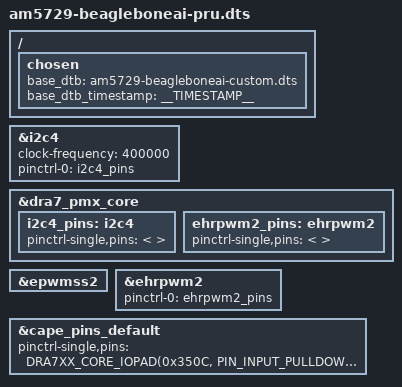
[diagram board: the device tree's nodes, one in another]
#include "am5729-beagleboneai.dts"  
// make it easy to determine which dtb you're currently running on  
// (via /proc/device-tree/chosen/)  
/ {  
 chosen {  
  base_dtb = "am5729-beagleboneai-custom.dts";  
  base_dtb_timestamp = __TIMESTAMP__;  
 };  
};  
// eventually these should be available in a header  
#define P9_14  (0x3400 + 4 * 107)  
#define P9_16  (0x3400 + 4 * 108)  
#define P9_19a (0x3400 + 4 * 16)  
#define P9_19b (0x3400 + 4 * 95)  
#define P9_20a (0x3400 + 4 * 17)  
#define P9_20b (0x3400 + 4 * 94)  
// enable i2c-3 on P9.19 (scl) + P9.20 (sda)  
&i2c4 {  
 status = "okay";  
 clock-frequency = <400000>;  
 pinctrl-names = "default";  
 pinctrl-0 = <&i2c4_pins>;  
};  
&dra7_pmx_core {  
 i2c4_pins: i2c4 {  
  pinctrl-single,pins = <  
   /* DRA7XX_CORE_IOPAD( P9_19a, PIN_INPUT_PULLUP | MUX_MODE7  )  // scl   */
   /* DRA7XX_CORE_IOPAD( P9_19b, PIN_INPUT_PULLUP | MUX_MODE14 )  // (shared pin)   */
   /* DRA7XX_CORE_IOPAD( P9_20a, PIN_INPUT_PULLUP | MUX_MODE7  )  // sda   */
   /* DRA7XX_CORE_IOPAD( P9_20b, PIN_INPUT_PULLUP | MUX_MODE14 )  // (shared pin)   */
  >;  
 };  
};  
// enable pwm-2 on P9.14 (out-A) + P9.16 (out-B)  
&epwmss2 {  
 status = "okay";  
};  
&ehrpwm2 {  
 status = "okay";  
 pinctrl-names = "default";  
 pinctrl-0 = <&ehrpwm2_pins>;  
};  
&dra7_pmx_core {  
 ehrpwm2_pins: ehrpwm2 {  
  pinctrl-single,pins = <  
 //  DRA7XX_CORE_IOPAD( P9_14, PIN_OUTPUT_PULLDOWN | MUX_MODE13 )  // out A  
 //  DRA7XX_CORE_IOPAD( P9_16, PIN_OUTPUT_PULLDOWN | MUX_MODE13 )  // out B  
  >;  
 };  
};  
  
// Here's the obnoxious part: since u-boot doesn't have same pin defaults yet, all pins not  
// explicitly setup above should be overridden here.  This will eventually no longer be needed.  
&cape_pins_default {  
 pinctrl-single,pins = <  
DRA7XX_CORE_IOPAD(0x350C, PIN_INPUT_PULLDOWN | MUX_MODE13) // P8.12(pr1_pru0_gpo3)
DRA7XX_CORE_IOPAD(0x3510, PIN_INPUT_PULLDOWN | MUX_MODE13) // P8.11(pr1_pru0_gpo4)
DRA7XX_CORE_IOPAD(0x3514, PIN_INPUT_PULLDOWN | MUX_MODE13) // P9.15(pr1_pru0_gpo5)
DRA7XX_CORE_IOPAD(0x3544, PIN_INPUT_PULLDOWN | MUX_MODE13) // P9.26(pr1_pru0_gpo17)
DRA7XX_CORE_IOPAD(0x3578, PIN_INPUT_PULLDOWN | MUX_MODE13) // P9.20(pr1_pru1_gpo1)
DRA7XX_CORE_IOPAD(0x357C, PIN_INPUT_PULLDOWN | MUX_MODE13) // P9.19(pr1_pru1_gpo2)
DRA7XX_CORE_IOPAD(0x3580, PIN_INPUT_PULLDOWN | MUX_MODE13) // P9.41(pr1_pru1_gpo3)
DRA7XX_CORE_IOPAD(0x3588, PIN_INPUT_PULLDOWN | MUX_MODE13) // P8.18(pr1_pru1_gpo5)
DRA7XX_CORE_IOPAD(0x358C, PIN_INPUT_PULLDOWN | MUX_MODE13) // P8.19(pr1_pru1_gpo6)
DRA7XX_CORE_IOPAD(0x3590, PIN_INPUT_PULLDOWN | MUX_MODE13) // P8.13(pr1_pru1_gpo7)
DRA7XX_CORE_IOPAD(0x3598, PIN_INPUT_PULLDOWN | MUX_MODE13) // P8.14(pr1_pru1_gpo9)
DRA7XX_CORE_IOPAD(0x359C, PIN_INPUT_PULLDOWN | MUX_MODE13) // P9.42(pr1_pru1_gpo10)
DRA7XX_CORE_IOPAD(0x35A0, PIN_INPUT_PULLDOWN | MUX_MODE13) // P9.27(pr1_pru1_gpo11)
DRA7XX_CORE_IOPAD(0x35AC, PIN_INPUT_PULLDOWN | MUX_MODE13) // P9.14(pr1_pru1_gpo14)
DRA7XX_CORE_IOPAD(0x35B0, PIN_INPUT_PULLDOWN | MUX_MODE13) // P9.16(pr1_pru1_gpo15)
DRA7XX_CORE_IOPAD(0x35B4, PIN_INPUT_PULLDOWN | MUX_MODE13) // P8.15(pr1_pru1_gpo16)
DRA7XX_CORE_IOPAD(0x35B8, PIN_INPUT_PULLDOWN | MUX_MODE13) // P8.26(pr1_pru1_gpo17)
DRA7XX_CORE_IOPAD(0x35BC, PIN_INPUT_PULLDOWN | MUX_MODE13) // P8.16(pr1_pru1_gpo18)
DRA7XX_CORE_IOPAD(0x35E8, PIN_INPUT_PULLDOWN | MUX_MODE13) // P8.44(pr2_pru0_gpo0)
DRA7XX_CORE_IOPAD(0x35EC, PIN_INPUT_PULLDOWN | MUX_MODE13) // P8.41(pr2_pru0_gpo1)
DRA7XX_CORE_IOPAD(0x377C, PIN_INPUT_PULLDOWN | MUX_MODE13) // P8.21(pr2_pru0_gpo2)
DRA7XX_CORE_IOPAD(0x35F0, PIN_INPUT_PULLDOWN | MUX_MODE13) // P8.42(pr2_pru0_gpo2)
DRA7XX_CORE_IOPAD(0x3780, PIN_INPUT_PULLDOWN | MUX_MODE13) // P8.20(pr2_pru0_gpo3)
DRA7XX_CORE_IOPAD(0x35F4, PIN_INPUT_PULLDOWN | MUX_MODE13) // P8.39(pr2_pru0_gpo3)
DRA7XX_CORE_IOPAD(0x3784, PIN_INPUT_PULLDOWN | MUX_MODE13) // P8.25(pr2_pru0_gpo4)
DRA7XX_CORE_IOPAD(0x35F8, PIN_INPUT_PULLDOWN | MUX_MODE13) // P8.40(pr2_pru0_gpo4)
DRA7XX_CORE_IOPAD(0x3788, PIN_INPUT_PULLDOWN | MUX_MODE13) // P8.24(pr2_pru0_gpo5)
DRA7XX_CORE_IOPAD(0x35FC, PIN_INPUT_PULLDOWN | MUX_MODE13) // P8.37(pr2_pru0_gpo5)
DRA7XX_CORE_IOPAD(0x378C, PIN_INPUT_PULLDOWN | MUX_MODE13) // P8.05(pr2_pru0_gpo6)
DRA7XX_CORE_IOPAD(0x3600, PIN_INPUT_PULLDOWN | MUX_MODE13) // P8.38(pr2_pru0_gpo6)
DRA7XX_CORE_IOPAD(0x3790, PIN_INPUT_PULLDOWN | MUX_MODE13) // P8.06(pr2_pru0_gpo7)
DRA7XX_CORE_IOPAD(0x3604, PIN_INPUT_PULLDOWN | MUX_MODE13) // P8.36(pr2_pru0_gpo7)
DRA7XX_CORE_IOPAD(0x3794, PIN_INPUT_PULLDOWN | MUX_MODE13) // P8.23(pr2_pru0_gpo8)
DRA7XX_CORE_IOPAD(0x3608, PIN_INPUT_PULLDOWN | MUX_MODE13) // P8.34(pr2_pru0_gpo8)
DRA7XX_CORE_IOPAD(0x3798, PIN_INPUT_PULLDOWN | MUX_MODE13) // P8.22(pr2_pru0_gpo9)
DRA7XX_CORE_IOPAD(0x360C, PIN_INPUT_PULLDOWN | MUX_MODE13) // P8.35(pr2_pru0_gpo9)
DRA7XX_CORE_IOPAD(0x379C, PIN_INPUT_PULLDOWN | MUX_MODE13) // P8.03(pr2_pru0_gpo10)
DRA7XX_CORE_IOPAD(0x3610, PIN_INPUT_PULLDOWN | MUX_MODE13) // P8.33(pr2_pru0_gpo10)
DRA7XX_CORE_IOPAD(0x37A0, PIN_INPUT_PULLDOWN | MUX_MODE13) // P8.04(pr2_pru0_gpo11)
DRA7XX_CORE_IOPAD(0x3614, PIN_INPUT_PULLDOWN | MUX_MODE13) // P8.31(pr2_pru0_gpo11)
DRA7XX_CORE_IOPAD(0x3618, PIN_INPUT_PULLDOWN | MUX_MODE13) // P8.32(pr2_pru0_gpo12)
DRA7XX_CORE_IOPAD(0x361C, PIN_INPUT_PULLDOWN | MUX_MODE13) // P8.45(pr2_pru0_gpo13)
DRA7XX_CORE_IOPAD(0x372C, PIN_INPUT_PULLDOWN | MUX_MODE13) // P9.11(pr2_pru0_gpo14)
DRA7XX_CORE_IOPAD(0x3620, PIN_INPUT_PULLDOWN | MUX_MODE13) // P9.11(pr2_pru0_gpo14)
DRA7XX_CORE_IOPAD(0x3730, PIN_INPUT_PULLDOWN | MUX_MODE13) // P9.13(pr2_pru0_gpo15)
DRA7XX_CORE_IOPAD(0x3624, PIN_INPUT_PULLDOWN | MUX_MODE13) // P8.17(pr2_pru0_gpo15)
DRA7XX_CORE_IOPAD(0x3628, PIN_INPUT_PULLDOWN | MUX_MODE13) // P8.27(pr2_pru0_gpo16)
DRA7XX_CORE_IOPAD(0x362C, PIN_INPUT_PULLDOWN | MUX_MODE13) // P8.28(pr2_pru0_gpo17)
DRA7XX_CORE_IOPAD(0x3630, PIN_INPUT_PULLDOWN | MUX_MODE13) // P8.29(pr2_pru0_gpo18)
DRA7XX_CORE_IOPAD(0x3634, PIN_INPUT_PULLDOWN | MUX_MODE13) // P8.30(pr2_pru0_gpo19)
DRA7XX_CORE_IOPAD(0x36F0, PIN_INPUT_PULLDOWN | MUX_MODE13) // P8.08(pr2_pru0_gpo20)
DRA7XX_CORE_IOPAD(0x3638, PIN_INPUT_PULLDOWN | MUX_MODE13) // P8.46(pr2_pru0_gpo20)
DRA7XX_CORE_IOPAD(0x3740, PIN_INPUT_PULLDOWN | MUX_MODE15) // P8.32(driver off)
DRA7XX_CORE_IOPAD(0x3694, PIN_INPUT_PULLDOWN | MUX_MODE13) // P9.25(pr2_pru1_gpo5)
DRA7XX_CORE_IOPAD(0x3698, PIN_INPUT_PULLDOWN | MUX_MODE13) // P8.09(pr2_pru1_gpo6)
DRA7XX_CORE_IOPAD(0x36A4, PIN_INPUT_PULLDOWN | MUX_MODE13) // P9.31(pr2_pru1_gpo7)
DRA7XX_CORE_IOPAD(0x36B4, PIN_INPUT_PULLDOWN | MUX_MODE13) // P9.18(pr2_pru1_gpo8)
DRA7XX_CORE_IOPAD(0x36B8, PIN_INPUT_PULLDOWN | MUX_MODE13) // P9.17(pr2_pru1_gpo9)
DRA7XX_CORE_IOPAD(0x36D4, PIN_INPUT_PULLDOWN | MUX_MODE15) // P9.31(driver off)
DRA7XX_CORE_IOPAD(0x36D8, PIN_INPUT_PULLDOWN | MUX_MODE13) // P9.29(pr2_pru1_gpo11)
DRA7XX_CORE_IOPAD(0x36DC, PIN_INPUT_PULLDOWN | MUX_MODE13) // P9.30(pr2_pru1_gpo12)
DRA7XX_CORE_IOPAD(0x36E0, PIN_INPUT_PULLDOWN | MUX_MODE13) // P9.28(pr2_pru1_gpo13)
DRA7XX_CORE_IOPAD(0x36E4, PIN_INPUT_PULLDOWN | MUX_MODE15) // P9.42(driver off)
DRA7XX_CORE_IOPAD(0x36E8, PIN_INPUT_PULLDOWN | MUX_MODE13) // P8.10(pr2_pru1_gpo15)
DRA7XX_CORE_IOPAD(0x36EC, PIN_INPUT_PULLDOWN | MUX_MODE13) // P8.07(pr2_pru1_gpo16)
DRA7XX_CORE_IOPAD(0x35D8, PIN_INPUT_PULLDOWN | MUX_MODE15) // P8.27(driver off)
DRA7XX_CORE_IOPAD(0x35DC, PIN_INPUT_PULLDOWN | MUX_MODE15) // P8.45(driver off)
DRA7XX_CORE_IOPAD(0x35E0, PIN_INPUT_PULLDOWN | MUX_MODE15) // P8.46(driver off)
DRA7XX_CORE_IOPAD(0x35E4, PIN_INPUT_PULLDOWN | MUX_MODE13) // P8.43(pr2_pru1_gpo20)
DRA7XX_CORE_IOPAD(0x3680, PIN_INPUT_PULLDOWN | MUX_MODE15) // P9.13(driver off)
DRA7XX_CORE_IOPAD(0x37CC, PIN_INPUT_PULLDOWN | MUX_MODE15) // P9.17(driver off)
DRA7XX_CORE_IOPAD(0x37C8, PIN_INPUT_PULLDOWN | MUX_MODE15) // P9.18(driver off)
DRA7XX_CORE_IOPAD(0x3440, PIN_INPUT_PULLDOWN | MUX_MODE15) // P9.19(driver off)
DRA7XX_CORE_IOPAD(0x3444, PIN_INPUT_PULLDOWN | MUX_MODE15) // P9.20(driver off)
DRA7XX_CORE_IOPAD(0x34F0, PIN_INPUT_PULLDOWN | MUX_MODE15) // P9.21(driver off)
DRA7XX_CORE_IOPAD(0x369C, PIN_INPUT_PULLDOWN | MUX_MODE15) // P9.22(driver off)
DRA7XX_CORE_IOPAD(0x3688, PIN_INPUT_PULLDOWN | MUX_MODE15) // P9.26(driver off)
DRA7XX_CORE_IOPAD(0x36B0, PIN_INPUT_PULLDOWN | MUX_MODE15) // P9.27(driver off)
DRA7XX_CORE_IOPAD(0x36A8, PIN_INPUT_PULLDOWN | MUX_MODE15) // P9.29(driver off)
DRA7XX_CORE_IOPAD(0x36A0, PIN_INPUT_PULLDOWN | MUX_MODE15) // P9.41(driver off)
DRA7XX_CORE_IOPAD(0x3570, PIN_INPUT_PULLDOWN | MUX_MODE15) // P8.15(driver off)
DRA7XX_CORE_IOPAD(0x35C8, PIN_INPUT_PULLDOWN | MUX_MODE15) // P8.28(driver off)
DRA7XX_CORE_IOPAD(0x35D4, PIN_INPUT_PULLDOWN | MUX_MODE15) // P8.29(driver off)
DRA7XX_CORE_IOPAD(0x35CC, PIN_INPUT_PULLDOWN | MUX_MODE15) // P8.30(driver off)
DRA7XX_CORE_IOPAD(0x373C, PIN_INPUT_PULLDOWN | MUX_MODE15) // P8.31(driver off)
DRA7XX_CORE_IOPAD(0x34E8, PIN_INPUT_PULLDOWN | MUX_MODE15) // P8.33(driver off)
DRA7XX_CORE_IOPAD(0x3564, PIN_INPUT_PULLDOWN | MUX_MODE15) // P8.34(driver off)
DRA7XX_CORE_IOPAD(0x34E4, PIN_INPUT_PULLDOWN | MUX_MODE15) // P8.35(driver off)
DRA7XX_CORE_IOPAD(0x3568, PIN_INPUT_PULLDOWN | MUX_MODE15) // P8.36(driver off)
DRA7XX_CORE_IOPAD(0x3738, PIN_INPUT_PULLDOWN | MUX_MODE15) // P8.37(driver off)
DRA7XX_CORE_IOPAD(0x3734, PIN_INPUT_PULLDOWN | MUX_MODE15) // P8.38(driver off)
 >;  
};  
